AUTOSAR XML (schema 4-2-2)
package /ComponentTypes
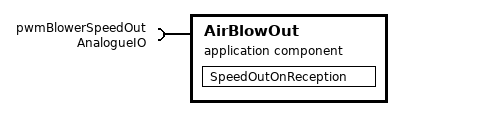
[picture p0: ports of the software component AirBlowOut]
  application sw component type AirBlowOut
    require port pwmBlowerSpeedOut: nonqueued-receiver-com-spec{data-element=speed, init-value=0}, required-interface=AnalogueIO
    behavior AirBlowOut_InternalBehavior: data-type-mapping=speedMapSet
      data received event DRT_SpeedOut_pwmBlowerSpeedOut_speed: start-on-event=SpeedOutOnReception, data=pwmBlowerSpeedOut.speed
      runnable SpeedOutOnReception
        data-receive-point-by-arguments:
          access REC_pwmBlowerSpeedOut_speed: accessed-variable=pwmBlowerSpeedOut.speed
  swc implementation AirBlowOut_Implementation: behavior=AirBlowOut_InternalBehavior
